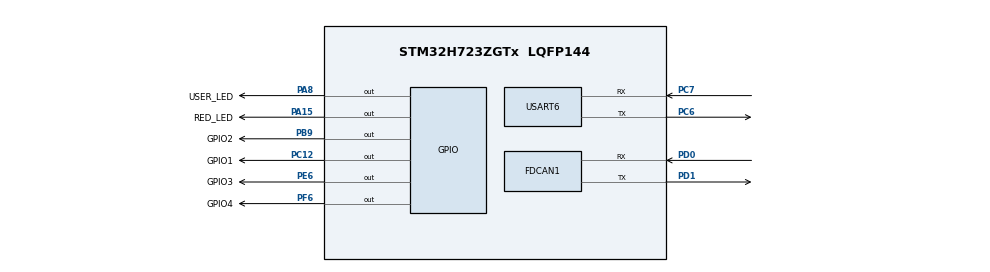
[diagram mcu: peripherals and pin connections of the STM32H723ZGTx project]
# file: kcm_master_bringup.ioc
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CORTEX_M7.default_mode_Activation=1
Dma.Request0=USART6_RX
Dma.USART6_RX.0.Direction=DMA_PERIPH_TO_MEMORY
Dma.USART6_RX.0.EventEnable=DISABLE
Dma.USART6_RX.0.FIFOMode=DMA_FIFOMODE_DISABLE
Dma.USART6_RX.0.Instance=DMA1_Stream0
Dma.USART6_RX.0.MemDataAlignment=DMA_MDATAALIGN_BYTE
Dma.USART6_RX.0.MemInc=DMA_MINC_ENABLE
Dma.USART6_RX.0.Mode=DMA_NORMAL
Dma.USART6_RX.0.PeriphDataAlignment=DMA_PDATAALIGN_BYTE
Dma.USART6_RX.0.PeriphInc=DMA_PINC_DISABLE
Dma.USART6_RX.0.Polarity=HAL_DMAMUX_REQ_GEN_RISING
Dma.USART6_RX.0.Priority=DMA_PRIORITY_LOW
Dma.USART6_RX.0.RequestNumber=1
Dma.USART6_RX.0.SignalID=NONE
Dma.USART6_RX.0.SyncEnable=DISABLE
Dma.USART6_RX.0.SyncPolarity=HAL_DMAMUX_SYNC_NO_EVENT
Dma.USART6_RX.0.SyncRequestNumber=1
Dma.USART6_RX.0.SyncSignalID=NONE
FDCAN1.AutoRetransmission=ENABLE
FDCAN1.CalculateBaudRateNominal=500000
FDCAN1.CalculateTimeBitNominal=2000
FDCAN1.CalculateTimeQuantumNominal=36.36363636363636
FDCAN1.NominalPrescaler=5
FDCAN1.NominalSyncJumpWidth=4
FDCAN1.NominalTimeSeg1=43
FDCAN1.NominalTimeSeg2=11
FDCAN1.RxFifo0ElmtsNbr=16
FDCAN1.TxFifoQueueElmtsNbr=8
Mcu.Family=STM32H7
Mcu.Name=STM32H723ZGTx
Mcu.Package=LQFP144
NVIC.DMA1_Stream0_IRQn=true\:0\:0\:false\:false\:true\:false\:true\:true
NVIC.FDCAN1_IT0_IRQn=true\:0\:0\:false\:false\:true\:true\:true\:true
NVIC.FDCAN1_IT1_IRQn=true\:0\:0\:false\:false\:true\:true\:true\:true
NVIC.PriorityGroup=NVIC_PRIORITYGROUP_4
NVIC.USART6_IRQn=true\:0\:0\:false\:false\:true\:true\:true\:true
PA13(JTMS/SWDIO).Mode=Serial_Wire
PA13(JTMS/SWDIO).Signal=DEBUG_JTMS-SWDIO
PA14(JTCK/SWCLK).Mode=Serial_Wire
PA14(JTCK/SWCLK).Signal=DEBUG_JTCK-SWCLK
PA15(JTDI).GPIO_Label=RED_LED
PA15(JTDI).Signal=GPIO_Output
PA8.GPIO_Label=USER_LED
PA8.Signal=GPIO_Output
PB9.GPIO_Label=GPIO2
PB9.Signal=GPIO_Output
PC12.GPIO_Label=GPIO1
PC12.Signal=GPIO_Output
PC6.Mode=Asynchronous
PC6.Signal=USART6_TX
PC7.Mode=Asynchronous
PC7.Signal=USART6_RX
PD0.Mode=FDCAN_Activate
PD0.Signal=FDCAN1_RX
PD1.Mode=FDCAN_Activate
PD1.Signal=FDCAN1_TX
PE6.GPIO_Label=GPIO3
PE6.Signal=GPIO_Output
PF6.GPIO_Label=GPIO4
PF6.Signal=GPIO_Output
PH0-OSC_IN.Mode=HSE-External-Clock-Source
PH0-OSC_IN.Signal=RCC_OSC_IN
ProjectManager.HeapSize=0x200
ProjectManager.StackSize=0x400
ProjectManager.TargetToolchain=CMake
RCC.ADCFreq_Value=129000000
RCC.APB1Freq_Value=137500000
RCC.APB2Freq_Value=137500000
RCC.APB3Freq_Value=137500000
RCC.APB4Freq_Value=137500000
RCC.CortexFreq_Value=550000000
RCC.D1PPRE=RCC_APB3_DIV2
RCC.D2PPRE1=RCC_APB1_DIV2
RCC.D2PPRE2=RCC_APB2_DIV2
RCC.D3PPRE=RCC_APB4_DIV2
RCC.DIVM1=4
RCC.DIVN1=34
RCC.DIVP1=1
RCC.DIVQ1=4
RCC.HCLKFreq_Value=275000000
RCC.HPRE=RCC_HCLK_DIV2
RCC.PLL2FRACN=0
RCC.PLL3FRACN=0
RCC.PLLFRACN=3072
RCC.SYSCLKFreq_VALUE=550000000
RCC.SYSCLKSource=RCC_SYSCLKSOURCE_PLLCLK
RCC.USBFreq_Value=137500000
TIM23.Channel-Output\ Compare1\ No\ Output=TIM_CHANNEL_1
TIM23.Prescaler=274
USART6.VirtualMode-Asynchronous=VM_ASYNC
VP_MEMORYMAP_VS_MEMORYMAP.Mode=CurAppReg
VP_TIM23_VS_no_output1.Mode=Output Compare1 No Output
board=custom

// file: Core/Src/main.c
/* USER CODE BEGIN Header */
/**
  ******************************************************************************
  * @file           : main.c
  * @brief          : Main program body
  ******************************************************************************
  * @attention
  *
  * Copyright (c) 2026 STMicroelectronics.
  * All rights reserved.
  *
  * This software is licensed under terms that can be found in the LICENSE file
  * in the root directory of this software component.
  * If no LICENSE file comes with this software, it is provided AS-IS.
  *
  ******************************************************************************
  */
/* USER CODE END Header */
#include "main.h"

/* USER CODE BEGIN Includes */
#include "functions.h"
/* USER CODE END Includes */

FDCAN_HandleTypeDef hfdcan1;

TIM_HandleTypeDef htim23;

UART_HandleTypeDef huart6;
DMA_HandleTypeDef hdma_usart6_rx;

void SystemClock_Config(void);
static void MPU_Config(void);
static void MX_GPIO_Init(void);
static void MX_DMA_Init(void);
static void MX_USART6_UART_Init(void);
static void MX_TIM23_Init(void);
static void MX_FDCAN1_Init(void);

int main(void)
{

  /* MPU Configuration--------------------------------------------------------*/
  MPU_Config();

  /* MCU Configuration--------------------------------------------------------*/

  /* Reset of all peripherals, Initializes the Flash interface and the Systick. */
  HAL_Init();

  /* Configure the system clock */
  SystemClock_Config();

  /* Initialize all configured peripherals */
  MX_GPIO_Init();
  MX_DMA_Init();
  MX_USART6_UART_Init();
  MX_TIM23_Init();
  MX_FDCAN1_Init();
  /* USER CODE BEGIN 2 */
  setup();
  /* USER CODE END 2 */

  /* Infinite loop */
  while (1)
  {

    /* USER CODE BEGIN 3 */
    loop();
  }
  /* USER CODE END 3 */
}

void SystemClock_Config(void)
{
  RCC_OscInitTypeDef RCC_OscInitStruct = {0};
  RCC_ClkInitTypeDef RCC_ClkInitStruct = {0};

  /** Supply configuration update enable
  */
  HAL_PWREx_ConfigSupply(PWR_LDO_SUPPLY);

  /** Configure the main internal regulator output voltage
  */
  __HAL_PWR_VOLTAGESCALING_CONFIG(PWR_REGULATOR_VOLTAGE_SCALE0);

  while(!__HAL_PWR_GET_FLAG(PWR_FLAG_VOSRDY)) {}

  /** Initializes the RCC Oscillators according to the specified parameters
  * in the RCC_OscInitTypeDef structure.
  */
  RCC_OscInitStruct.OscillatorType = RCC_OSCILLATORTYPE_HSI;
  RCC_OscInitStruct.HSIState = RCC_HSI_DIV1;
  RCC_OscInitStruct.HSICalibrationValue = 64;
  RCC_OscInitStruct.PLL.PLLState = RCC_PLL_ON;
  RCC_OscInitStruct.PLL.PLLSource = RCC_PLLSOURCE_HSI;
  RCC_OscInitStruct.PLL.PLLM = 4;
  RCC_OscInitStruct.PLL.PLLN = 34;
  RCC_OscInitStruct.PLL.PLLP = 1;
  RCC_OscInitStruct.PLL.PLLQ = 4;
  RCC_OscInitStruct.PLL.PLLR = 2;
  RCC_OscInitStruct.PLL.PLLRGE = RCC_PLL1VCIRANGE_3;
  RCC_OscInitStruct.PLL.PLLVCOSEL = RCC_PLL1VCOWIDE;
  RCC_OscInitStruct.PLL.PLLFRACN = 3072;
  if (HAL_RCC_OscConfig(&RCC_OscInitStruct) != HAL_OK)
  {
    Error_Handler();
  }

  /** Initializes the CPU, AHB and APB buses clocks
  */
  RCC_ClkInitStruct.ClockType = RCC_CLOCKTYPE_HCLK|RCC_CLOCKTYPE_SYSCLK
                              |RCC_CLOCKTYPE_PCLK1|RCC_CLOCKTYPE_PCLK2
                              |RCC_CLOCKTYPE_D3PCLK1|RCC_CLOCKTYPE_D1PCLK1;
  RCC_ClkInitStruct.SYSCLKSource = RCC_SYSCLKSOURCE_PLLCLK;
  RCC_ClkInitStruct.SYSCLKDivider = RCC_SYSCLK_DIV1;
  RCC_ClkInitStruct.AHBCLKDivider = RCC_HCLK_DIV2;
  RCC_ClkInitStruct.APB3CLKDivider = RCC_APB3_DIV2;
  RCC_ClkInitStruct.APB1CLKDivider = RCC_APB1_DIV2;
  RCC_ClkInitStruct.APB2CLKDivider = RCC_APB2_DIV2;
  RCC_ClkInitStruct.APB4CLKDivider = RCC_APB4_DIV2;

  if (HAL_RCC_ClockConfig(&RCC_ClkInitStruct, FLASH_LATENCY_3) != HAL_OK)
  {
    Error_Handler();
  }
}

static void MX_FDCAN1_Init(void)
{

  hfdcan1.Instance = FDCAN1;
  hfdcan1.Init.FrameFormat = FDCAN_FRAME_CLASSIC;
  hfdcan1.Init.Mode = FDCAN_MODE_NORMAL;
  hfdcan1.Init.AutoRetransmission = ENABLE;
  hfdcan1.Init.TransmitPause = DISABLE;
  hfdcan1.Init.ProtocolException = DISABLE;
  hfdcan1.Init.NominalPrescaler = 5;
  hfdcan1.Init.NominalSyncJumpWidth = 4;
  hfdcan1.Init.NominalTimeSeg1 = 43;
  hfdcan1.Init.NominalTimeSeg2 = 11;
  hfdcan1.Init.DataPrescaler = 1;
  hfdcan1.Init.DataSyncJumpWidth = 1;
  hfdcan1.Init.DataTimeSeg1 = 1;
  hfdcan1.Init.DataTimeSeg2 = 1;
  hfdcan1.Init.MessageRAMOffset = 0;
  hfdcan1.Init.StdFiltersNbr = 0;
  hfdcan1.Init.ExtFiltersNbr = 0;
  hfdcan1.Init.RxFifo0ElmtsNbr = 16;
  hfdcan1.Init.RxFifo0ElmtSize = FDCAN_DATA_BYTES_8;
  hfdcan1.Init.RxFifo1ElmtsNbr = 0;
  hfdcan1.Init.RxFifo1ElmtSize = FDCAN_DATA_BYTES_8;
  hfdcan1.Init.RxBuffersNbr = 0;
  hfdcan1.Init.RxBufferSize = FDCAN_DATA_BYTES_8;
  hfdcan1.Init.TxEventsNbr = 0;
  hfdcan1.Init.TxBuffersNbr = 0;
  hfdcan1.Init.TxFifoQueueElmtsNbr = 8;
  hfdcan1.Init.TxFifoQueueMode = FDCAN_TX_FIFO_OPERATION;
  hfdcan1.Init.TxElmtSize = FDCAN_DATA_BYTES_8;
  if (HAL_FDCAN_Init(&hfdcan1) != HAL_OK)
  {
    Error_Handler();
  }

}

static void MX_TIM23_Init(void)
{

  TIM_MasterConfigTypeDef sMasterConfig = {0};
  TIM_OC_InitTypeDef sConfigOC = {0};

  htim23.Instance = TIM23;
  htim23.Init.Prescaler = 274;
  htim23.Init.CounterMode = TIM_COUNTERMODE_UP;
  htim23.Init.Period = 4294967295;
  htim23.Init.ClockDivision = TIM_CLOCKDIVISION_DIV1;
  htim23.Init.AutoReloadPreload = TIM_AUTORELOAD_PRELOAD_DISABLE;
  if (HAL_TIM_OC_Init(&htim23) != HAL_OK)
  {
    Error_Handler();
  }
  sMasterConfig.MasterOutputTrigger = TIM_TRGO_RESET;
  sMasterConfig.MasterSlaveMode = TIM_MASTERSLAVEMODE_DISABLE;
  if (HAL_TIMEx_MasterConfigSynchronization(&htim23, &sMasterConfig) != HAL_OK)
  {
    Error_Handler();
  }
  sConfigOC.OCMode = TIM_OCMODE_TIMING;
  sConfigOC.Pulse = 0;
  sConfigOC.OCPolarity = TIM_OCPOLARITY_HIGH;
  sConfigOC.OCFastMode = TIM_OCFAST_DISABLE;
  if (HAL_TIM_OC_ConfigChannel(&htim23, &sConfigOC, TIM_CHANNEL_1) != HAL_OK)
  {
    Error_Handler();
  }

}

static void MX_USART6_UART_Init(void)
{

  huart6.Instance = USART6;
  huart6.Init.BaudRate = 115200;
  huart6.Init.WordLength = UART_WORDLENGTH_8B;
  huart6.Init.StopBits = UART_STOPBITS_1;
  huart6.Init.Parity = UART_PARITY_NONE;
  huart6.Init.Mode = UART_MODE_TX_RX;
  huart6.Init.HwFlowCtl = UART_HWCONTROL_NONE;
  huart6.Init.OverSampling = UART_OVERSAMPLING_16;
  huart6.Init.OneBitSampling = UART_ONE_BIT_SAMPLE_DISABLE;
  huart6.Init.ClockPrescaler = UART_PRESCALER_DIV1;
  huart6.AdvancedInit.AdvFeatureInit = UART_ADVFEATURE_NO_INIT;
  if (HAL_UART_Init(&huart6) != HAL_OK)
  {
    Error_Handler();
  }
  if (HAL_UARTEx_SetTxFifoThreshold(&huart6, UART_TXFIFO_THRESHOLD_1_8) != HAL_OK)
  {
    Error_Handler();
  }
  if (HAL_UARTEx_SetRxFifoThreshold(&huart6, UART_RXFIFO_THRESHOLD_1_8) != HAL_OK)
  {
    Error_Handler();
  }
  if (HAL_UARTEx_DisableFifoMode(&huart6) != HAL_OK)
  {
    Error_Handler();
  }

}

static void MX_DMA_Init(void)
{

  /* DMA controller clock enable */
  __HAL_RCC_DMA1_CLK_ENABLE();

  /* DMA interrupt init */
  /* DMA1_Stream0_IRQn interrupt configuration */
  HAL_NVIC_SetPriority(DMA1_Stream0_IRQn, 0, 0);
  HAL_NVIC_EnableIRQ(DMA1_Stream0_IRQn);

}

static void MX_GPIO_Init(void)
{
  GPIO_InitTypeDef GPIO_InitStruct = {0};

  /* GPIO Ports Clock Enable */
  __HAL_RCC_GPIOE_CLK_ENABLE();
  __HAL_RCC_GPIOF_CLK_ENABLE();
  __HAL_RCC_GPIOH_CLK_ENABLE();
  __HAL_RCC_GPIOC_CLK_ENABLE();
  __HAL_RCC_GPIOA_CLK_ENABLE();
  __HAL_RCC_GPIOD_CLK_ENABLE();
  __HAL_RCC_GPIOB_CLK_ENABLE();

  /*Configure GPIO pin Output Level */
  HAL_GPIO_WritePin(GPIO3_GPIO_Port, GPIO3_Pin, GPIO_PIN_RESET);

  /*Configure GPIO pin Output Level */
  HAL_GPIO_WritePin(GPIO4_GPIO_Port, GPIO4_Pin, GPIO_PIN_RESET);

  /*Configure GPIO pin Output Level */
  HAL_GPIO_WritePin(GPIOA, USER_LED_Pin|RED_LED_Pin, GPIO_PIN_RESET);

  /*Configure GPIO pin Output Level */
  HAL_GPIO_WritePin(GPIO1_GPIO_Port, GPIO1_Pin, GPIO_PIN_RESET);

  /*Configure GPIO pin Output Level */
  HAL_GPIO_WritePin(GPIO2_GPIO_Port, GPIO2_Pin, GPIO_PIN_RESET);

  /*Configure GPIO pin : GPIO3_Pin */
  GPIO_InitStruct.Pin = GPIO3_Pin;
  GPIO_InitStruct.Mode = GPIO_MODE_OUTPUT_PP;
  GPIO_InitStruct.Pull = GPIO_NOPULL;
  GPIO_InitStruct.Speed = GPIO_SPEED_FREQ_LOW;
  HAL_GPIO_Init(GPIO3_GPIO_Port, &GPIO_InitStruct);

  /*Configure GPIO pin : GPIO4_Pin */
  GPIO_InitStruct.Pin = GPIO4_Pin;
  GPIO_InitStruct.Mode = GPIO_MODE_OUTPUT_PP;
  GPIO_InitStruct.Pull = GPIO_NOPULL;
  GPIO_InitStruct.Speed = GPIO_SPEED_FREQ_LOW;
  HAL_GPIO_Init(GPIO4_GPIO_Port, &GPIO_InitStruct);

  /*Configure GPIO pins : USER_LED_Pin RED_LED_Pin */
  GPIO_InitStruct.Pin = USER_LED_Pin|RED_LED_Pin;
  GPIO_InitStruct.Mode = GPIO_MODE_OUTPUT_PP;
  GPIO_InitStruct.Pull = GPIO_NOPULL;
  GPIO_InitStruct.Speed = GPIO_SPEED_FREQ_LOW;
  HAL_GPIO_Init(GPIOA, &GPIO_InitStruct);

  /*Configure GPIO pin : GPIO1_Pin */
  GPIO_InitStruct.Pin = GPIO1_Pin;
  GPIO_InitStruct.Mode = GPIO_MODE_OUTPUT_PP;
  GPIO_InitStruct.Pull = GPIO_NOPULL;
  GPIO_InitStruct.Speed = GPIO_SPEED_FREQ_LOW;
  HAL_GPIO_Init(GPIO1_GPIO_Port, &GPIO_InitStruct);

  /*Configure GPIO pin : GPIO2_Pin */
  GPIO_InitStruct.Pin = GPIO2_Pin;
  GPIO_InitStruct.Mode = GPIO_MODE_OUTPUT_PP;
  GPIO_InitStruct.Pull = GPIO_NOPULL;
  GPIO_InitStruct.Speed = GPIO_SPEED_FREQ_LOW;
  HAL_GPIO_Init(GPIO2_GPIO_Port, &GPIO_InitStruct);

}

 /* MPU Configuration */

void MPU_Config(void)
{
  MPU_Region_InitTypeDef MPU_InitStruct = {0};

  /* Disables the MPU */
  HAL_MPU_Disable();

  /** Initializes and configures the Region and the memory to be protected
  */
  MPU_InitStruct.Enable = MPU_REGION_ENABLE;
  MPU_InitStruct.Number = MPU_REGION_NUMBER0;
  MPU_InitStruct.BaseAddress = 0x0;
  MPU_InitStruct.Size = MPU_REGION_SIZE_4GB;
  MPU_InitStruct.SubRegionDisable = 0x87;
  MPU_InitStruct.TypeExtField = MPU_TEX_LEVEL0;
  MPU_InitStruct.AccessPermission = MPU_REGION_NO_ACCESS;
  MPU_InitStruct.DisableExec = MPU_INSTRUCTION_ACCESS_DISABLE;
  MPU_InitStruct.IsShareable = MPU_ACCESS_SHAREABLE;
  MPU_InitStruct.IsCacheable = MPU_ACCESS_NOT_CACHEABLE;
  MPU_InitStruct.IsBufferable = MPU_ACCESS_NOT_BUFFERABLE;

  HAL_MPU_ConfigRegion(&MPU_InitStruct);
  /* Enables the MPU */
  HAL_MPU_Enable(MPU_PRIVILEGED_DEFAULT);

}

void Error_Handler(void)
{
  __disable_irq();
  while (1)
  {
  }
}
